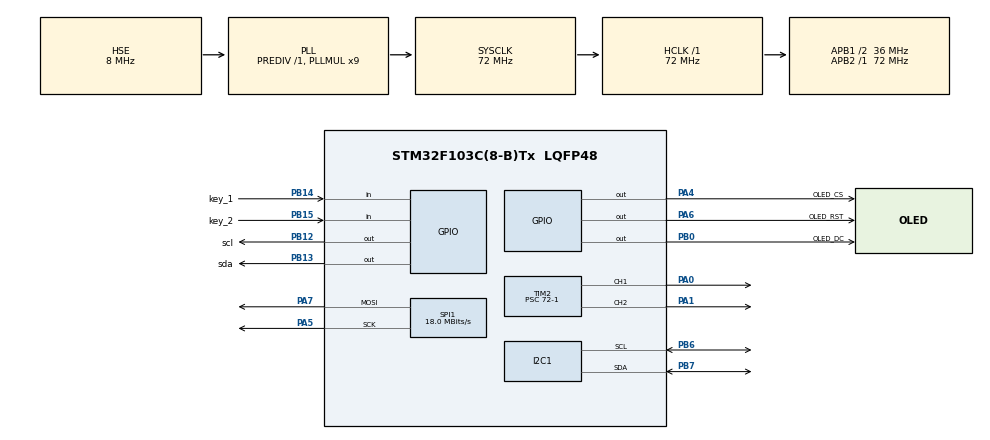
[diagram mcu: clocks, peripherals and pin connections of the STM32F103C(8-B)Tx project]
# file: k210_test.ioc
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Mcu.Family=STM32F1
Mcu.Name=STM32F103C(8-B)Tx
Mcu.Package=LQFP48
NVIC.I2C1_ER_IRQn=true\:0\:0\:false\:false\:true\:true\:true\:true
NVIC.PriorityGroup=NVIC_PRIORITYGROUP_4
NVIC.TIM1_UP_IRQn=true\:0\:0\:false\:false\:true\:true\:true\:true
PA0-WKUP.Signal=S_TIM2_CH1_ETR
PA1.Signal=S_TIM2_CH2
PA13.Mode=Serial_Wire
PA13.Signal=SYS_JTMS-SWDIO
PA14.Mode=Serial_Wire
PA14.Signal=SYS_JTCK-SWCLK
PA4.GPIO_Label=OLED_CS
PA4.Signal=GPIO_Output
PA5.Mode=TX_Only_Simplex_Unidirect_Master
PA5.Signal=SPI1_SCK
PA6.GPIO_Label=OLED_RST
PA6.Signal=GPIO_Output
PA7.Mode=TX_Only_Simplex_Unidirect_Master
PA7.Signal=SPI1_MOSI
PB0.GPIO_Label=OLED_DC
PB0.Signal=GPIO_Output
PB12.GPIO_Label=scl
PB12.GPIO_ModeDefaultOutputPP=GPIO_MODE_OUTPUT_OD
PB12.GPIO_PuPd=GPIO_PULLUP
PB12.GPIO_Speed=GPIO_SPEED_FREQ_HIGH
PB12.PinState=GPIO_PIN_SET
PB12.Signal=GPIO_Output
PB13.GPIO_Label=sda
PB13.GPIO_ModeDefaultOutputPP=GPIO_MODE_OUTPUT_OD
PB13.GPIO_PuPd=GPIO_PULLUP
PB13.GPIO_Speed=GPIO_SPEED_FREQ_HIGH
PB13.PinState=GPIO_PIN_SET
PB13.Signal=GPIO_Output
PB14.GPIO_Label=key_1
PB14.GPIO_PuPd=GPIO_PULLUP
PB14.Signal=GPIO_Input
PB15.GPIO_Label=key_2
PB15.GPIO_PuPd=GPIO_PULLUP
PB15.Signal=GPIO_Input
PB6.Mode=I2C
PB6.Signal=I2C1_SCL
PB7.Mode=I2C
PB7.Signal=I2C1_SDA
PD0-OSC_IN.Mode=HSE-External-Oscillator
PD0-OSC_IN.Signal=RCC_OSC_IN
PD1-OSC_OUT.Mode=HSE-External-Oscillator
PD1-OSC_OUT.Signal=RCC_OSC_OUT
ProjectManager.HeapSize=0x200
ProjectManager.StackSize=0x400
ProjectManager.TargetToolchain=MDK-ARM V5.32
RCC.AHBFreq_Value=72000000
RCC.APB1CLKDivider=RCC_HCLK_DIV2
RCC.APB1Freq_Value=36000000
RCC.APB1TimFreq_Value=72000000
RCC.APB2Freq_Value=72000000
RCC.APB2TimFreq_Value=72000000
RCC.HCLKFreq_Value=72000000
RCC.PLLMUL=RCC_PLL_MUL9
RCC.PLLSourceVirtual=RCC_PLLSOURCE_HSE
RCC.SYSCLKFreq_VALUE=72000000
RCC.SYSCLKSource=RCC_SYSCLKSOURCE_PLLCLK
RCC.USBFreq_Value=72000000
SH.S_TIM2_CH1_ETR.0=TIM2_CH1,PWM Generation1 CH1
SH.S_TIM2_CH2.0=TIM2_CH2,PWM Generation2 CH2
SPI1.BaudRatePrescaler=SPI_BAUDRATEPRESCALER_4
SPI1.CalculateBaudRate=18.0 MBits/s
SPI1.Direction=SPI_DIRECTION_2LINES
SPI1.Mode=SPI_MODE_MASTER
SPI1.VirtualType=VM_MASTER
TIM1.Period=1000-1
TIM1.Prescaler=72-1
TIM2.Channel-PWM\ Generation1\ CH1=TIM_CHANNEL_1
TIM2.Channel-PWM\ Generation2\ CH2=TIM_CHANNEL_2
TIM2.Period=100-1
TIM2.Prescaler=72-1
VP_TIM1_VS_ClockSourceINT.Mode=Internal
board=custom

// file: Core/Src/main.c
/* USER CODE BEGIN Header */
/**
  ******************************************************************************
  * @file           : main.c
  * @brief          : Main program body
  ******************************************************************************
  * @attention
  *
  * Copyright (c) 2025 STMicroelectronics.
  * All rights reserved.
  *
  * This software is licensed under terms that can be found in the LICENSE file
  * in the root directory of this software component.
  * If no LICENSE file comes with this software, it is provided AS-IS.
  *
  ******************************************************************************
  */
/* USER CODE END Header */
#include "main.h"
#include "i2c.h"
#include "spi.h"
#include "tim.h"
#include "gpio.h"

/* USER CODE BEGIN Includes */
#include "myMain.h"
/* USER CODE END Includes */

void SystemClock_Config(void);

int main(void)
{

  /* MCU Configuration--------------------------------------------------------*/

  /* Reset of all peripherals, Initializes the Flash interface and the Systick. */
  HAL_Init();

  /* Configure the system clock */
  SystemClock_Config();

  /* Initialize all configured peripherals */
  MX_GPIO_Init();
  MX_SPI1_Init();
  MX_TIM1_Init();
  MX_TIM2_Init();
  MX_I2C1_Init();
  /* USER CODE BEGIN 2 */
  HAL_TIM_Base_Start_IT(&htim1);
  HAL_TIM_PWM_Start(&htim2, TIM_CHANNEL_1);
  HAL_TIM_PWM_Start(&htim2, TIM_CHANNEL_2);
  setup();
  /* USER CODE END 2 */

  /* Infinite loop */
  /* USER CODE BEGIN WHILE */
  while (1)
  {
    loop();
    /* USER CODE END WHILE */

  }
}

void SystemClock_Config(void)
{
  RCC_OscInitTypeDef RCC_OscInitStruct = {0};
  RCC_ClkInitTypeDef RCC_ClkInitStruct = {0};

  /** Initializes the RCC Oscillators according to the specified parameters
  * in the RCC_OscInitTypeDef structure.
  */
  RCC_OscInitStruct.OscillatorType = RCC_OSCILLATORTYPE_HSE;
  RCC_OscInitStruct.HSEState = RCC_HSE_ON;
  RCC_OscInitStruct.HSEPredivValue = RCC_HSE_PREDIV_DIV1;
  RCC_OscInitStruct.HSIState = RCC_HSI_ON;
  RCC_OscInitStruct.PLL.PLLState = RCC_PLL_ON;
  RCC_OscInitStruct.PLL.PLLSource = RCC_PLLSOURCE_HSE;
  RCC_OscInitStruct.PLL.PLLMUL = RCC_PLL_MUL9;
  if (HAL_RCC_OscConfig(&RCC_OscInitStruct) != HAL_OK)
  {
    Error_Handler();
  }

  /** Initializes the CPU, AHB and APB buses clocks
  */
  RCC_ClkInitStruct.ClockType = RCC_CLOCKTYPE_HCLK|RCC_CLOCKTYPE_SYSCLK
                              |RCC_CLOCKTYPE_PCLK1|RCC_CLOCKTYPE_PCLK2;
  RCC_ClkInitStruct.SYSCLKSource = RCC_SYSCLKSOURCE_PLLCLK;
  RCC_ClkInitStruct.AHBCLKDivider = RCC_SYSCLK_DIV1;
  RCC_ClkInitStruct.APB1CLKDivider = RCC_HCLK_DIV2;
  RCC_ClkInitStruct.APB2CLKDivider = RCC_HCLK_DIV1;

  if (HAL_RCC_ClockConfig(&RCC_ClkInitStruct, FLASH_LATENCY_2) != HAL_OK)
  {
    Error_Handler();
  }
}

void Error_Handler(void)
{
  __disable_irq();
  while (1)
  {
  }
}
